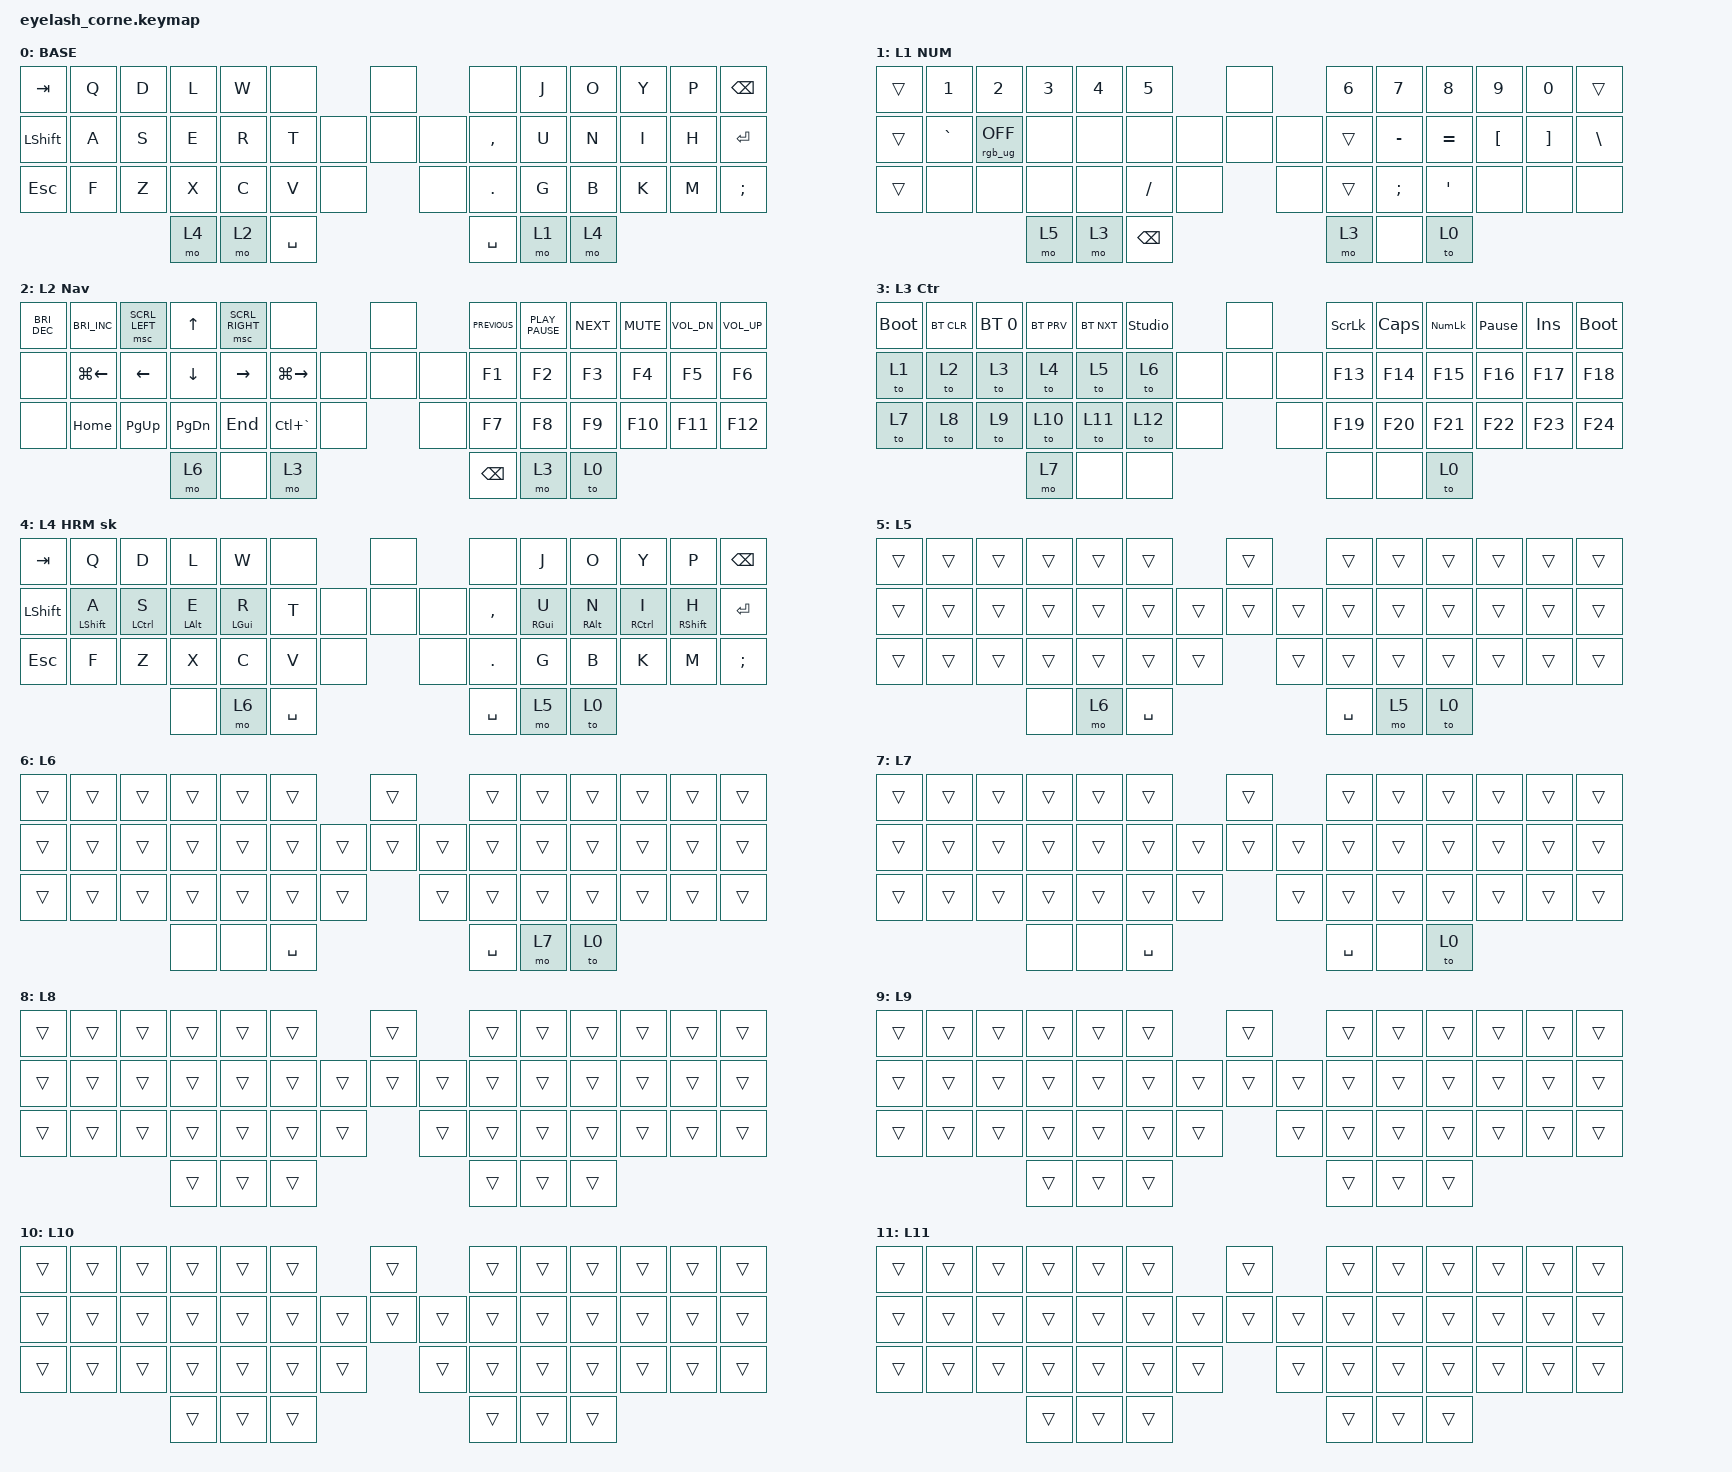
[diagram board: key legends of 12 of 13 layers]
#define ZMK_POINTING_DEFAULT_MOVE_VAL 1200  // 600
#define ZMK_POINTING_DEFAULT_SCRL_VAL 25   // 10

#include <input/processors.dtsi>
#include <zephyr/dt-bindings/input/input-event-codes.h>
#include <behaviors.dtsi>
#include <dt-bindings/zmk/bt.h>
#include <dt-bindings/zmk/keys.h>
#include <dt-bindings/zmk/pointing.h>
#include <dt-bindings/zmk/rgb.h>

&mmv_input_listener { input-processors = <&zip_xy_scaler 2 1>; };

&msc_input_listener { input-processors = <&zip_scroll_scaler 2 1>; };

/ {
    behaviors {
        td0: td0 {
            compatible = "zmk,behavior-tap-dance";
            display-name = "Shift/Caps Lock Tap Dance";
            #binding-cells = <0>;
            bindings = <&kp LEFT_SHIFT>, <&kp CAPS>;
        };
    };

    scroll_encoder: scroll_encoder {
        compatible = "zmk,behavior-sensor-rotate";
        #sensor-binding-cells = <0>;
        bindings = <&msc SCRL_DOWN>, <&msc SCRL_UP>;

        tap-ms = <100>;
    };

    keymap {
        compatible = "zmk,keymap";

        base {
            display-name = "BASE";
            bindings = <
&kp TAB    &kp Q  &kp D  &kp L  &kp W  &none                      &none         &none      &kp J  &kp O  &kp Y  &kp P  &kp BSPC
&kp LSHFT  &kp A  &kp S  &kp E  &kp R  &kp T               &none  &none  &none  &kp COMMA  &kp U  &kp N  &kp I  &kp H  &kp RET
&kp ESC    &kp F  &kp Z  &kp X  &kp C  &kp V      &none           &none         &kp DOT    &kp G  &kp B  &kp K  &kp M  &kp SEMI
                         &mo 4  &mo 2  &kp SPACE                                &kp SPACE  &mo 1  &mo 4
            >;
        };

        L1_Num {
            display-name = "L1 NUM";
            bindings = <
&trans  &kp N1     &kp N2           &kp N3  &kp N4  &kp N5                         &none         &kp N6  &kp N7     &kp N8     &kp N9    &kp N0    &trans
&trans  &kp GRAVE  &rgb_ug RGB_OFF  &none   &none   &none                   &none  &none  &none  &trans  &kp MINUS  &kp EQUAL  &kp LBKT  &kp RBKT  &kp BSLH
&trans  &none      &none            &none   &none   &kp FSLH       &none           &none         &trans  &kp SEMI   &kp SQT    &none     &none     &none
                                    &mo 5   &mo 3   &kp BACKSPACE                                &mo 3   &none      &to 0
            >;
        };

        L2_Nav {
            display-name = "L2 Nav";
            bindings = <
&kp C_BRIGHTNESS_DEC  &kp C_BRIGHTNESS_INC  &msc SCRL_LEFT  &kp UP         &msc SCRL_RIGHT  &none                          &none         &kp K_PREVIOUS  &kp K_PLAY_PAUSE  &kp K_NEXT  &kp K_MUTE  &kp K_VOL_DN  &kp K_VOLUME_UP
&none                 &kp LG(LEFT)          &kp LEFT        &kp DOWN       &kp RIGHT        &kp LG(RIGHT)           &none  &none  &none  &kp F1          &kp F2            &kp F3      &kp F4      &kp F5        &kp F6
&none                 &kp HOME              &kp PAGE_UP     &kp PAGE_DOWN  &kp END          &kp LC(GRAVE)  &none           &none         &kp F7          &kp F8            &kp F9      &kp F10     &kp F11       &kp F12
                                                            &mo 6          &none            &mo 3                                        &kp BACKSPACE   &mo 3             &to 0
            >;
        };

        L3_FN2_Ctr {
            display-name = "L3 Ctr";
            bindings = <
&bootloader  &bt BT_CLR  &bt BT_SEL 0  &bt BT_PRV  &bt BT_NXT  &studio_unlock                  &none         &kp SCROLLLOCK  &kp CAPS  &kp KP_NUMLOCK  &kp PAUSE_BREAK  &kp INSERT  &bootloader
&to 1        &to 2       &to 3         &to 4       &to 5       &to 6                    &none  &none  &none  &kp F13         &kp F14   &kp F15         &kp F16          &kp F17     &kp F18
&to 7        &to 8       &to 9         &to 10      &to 11      &to 12          &none           &none         &kp F19         &kp F20   &kp F21         &kp F22          &kp F23     &kp F24
                                       &mo 7       &none       &none                                         &none           &none     &to 0
            >;
        };

        L4_HRM {
            display-name = "L4 HRM sk";
            bindings = <
&kp TAB    &kp Q         &kp D        &kp L       &kp W       &none                      &none         &none      &kp J       &kp O       &kp Y        &kp P         &kp BSPC
&kp LSHFT  &mt LSHIFT A  &mt LCTRL S  &mt LALT E  &mt LGUI R  &kp T               &none  &none  &none  &kp COMMA  &mt RGUI U  &mt RALT N  &mt RCTRL I  &mt RSHIFT H  &kp RET
&kp ESC    &kp F         &kp Z        &kp X       &kp C       &kp V      &none           &none         &kp DOT    &kp G       &kp B       &kp K        &kp M         &kp SEMI
                                      &none       &mo 6       &kp SPACE                                &kp SPACE  &mo 5       &to 0
            >;
        };

        layer_5 {
            display-name = "L5";
            bindings = <
&trans  &trans  &trans  &trans  &trans  &trans                       &trans          &trans     &trans  &trans  &trans  &trans  &trans
&trans  &trans  &trans  &trans  &trans  &trans               &trans  &trans  &trans  &trans     &trans  &trans  &trans  &trans  &trans
&trans  &trans  &trans  &trans  &trans  &trans     &trans            &trans          &trans     &trans  &trans  &trans  &trans  &trans
                        &none   &mo 6   &kp SPACE                                    &kp SPACE  &mo 5   &to 0
            >;
        };

        layer_6 {
            display-name = "L6";
            bindings = <
&trans  &trans  &trans  &trans  &trans  &trans                       &trans          &trans     &trans  &trans  &trans  &trans  &trans
&trans  &trans  &trans  &trans  &trans  &trans               &trans  &trans  &trans  &trans     &trans  &trans  &trans  &trans  &trans
&trans  &trans  &trans  &trans  &trans  &trans     &trans            &trans          &trans     &trans  &trans  &trans  &trans  &trans
                        &none   &none   &kp SPACE                                    &kp SPACE  &mo 7   &to 0
            >;
        };

        layer_7 {
            display-name = "L7";
            bindings = <
&trans  &trans  &trans  &trans  &trans  &trans                       &trans          &trans     &trans  &trans  &trans  &trans  &trans
&trans  &trans  &trans  &trans  &trans  &trans               &trans  &trans  &trans  &trans     &trans  &trans  &trans  &trans  &trans
&trans  &trans  &trans  &trans  &trans  &trans     &trans            &trans          &trans     &trans  &trans  &trans  &trans  &trans
                        &none   &none   &kp SPACE                                    &kp SPACE  &none   &to 0
            >;
        };

        layer_8 {
            display-name = "L8";
            bindings = <
&trans  &trans  &trans  &trans  &trans  &trans                    &trans          &trans  &trans  &trans  &trans  &trans  &trans
&trans  &trans  &trans  &trans  &trans  &trans            &trans  &trans  &trans  &trans  &trans  &trans  &trans  &trans  &trans
&trans  &trans  &trans  &trans  &trans  &trans  &trans            &trans          &trans  &trans  &trans  &trans  &trans  &trans
                        &trans  &trans  &trans                                    &trans  &trans  &trans
            >;
        };

        layer_9 {
            display-name = "L9";
            bindings = <
&trans  &trans  &trans  &trans  &trans  &trans                    &trans          &trans  &trans  &trans  &trans  &trans  &trans
&trans  &trans  &trans  &trans  &trans  &trans            &trans  &trans  &trans  &trans  &trans  &trans  &trans  &trans  &trans
&trans  &trans  &trans  &trans  &trans  &trans  &trans            &trans          &trans  &trans  &trans  &trans  &trans  &trans
                        &trans  &trans  &trans                                    &trans  &trans  &trans
            >;
        };

        layer_10 {
            display-name = "L10";
            bindings = <
&trans  &trans  &trans  &trans  &trans  &trans                    &trans          &trans  &trans  &trans  &trans  &trans  &trans
&trans  &trans  &trans  &trans  &trans  &trans            &trans  &trans  &trans  &trans  &trans  &trans  &trans  &trans  &trans
&trans  &trans  &trans  &trans  &trans  &trans  &trans            &trans          &trans  &trans  &trans  &trans  &trans  &trans
                        &trans  &trans  &trans                                    &trans  &trans  &trans
            >;
        };

        layer_11 {
            display-name = "L11";
            bindings = <
&trans  &trans  &trans  &trans  &trans  &trans                    &trans          &trans  &trans  &trans  &trans  &trans  &trans
&trans  &trans  &trans  &trans  &trans  &trans            &trans  &trans  &trans  &trans  &trans  &trans  &trans  &trans  &trans
&trans  &trans  &trans  &trans  &trans  &trans  &trans            &trans          &trans  &trans  &trans  &trans  &trans  &trans
                        &trans  &trans  &trans                                    &trans  &trans  &trans
            >;
        };

        layer_12 {
            display-name = "L12";
            bindings = <
&trans  &trans  &trans  &trans  &trans  &trans                    &trans          &trans  &trans  &trans  &trans  &trans  &trans
&trans  &trans  &trans  &trans  &trans  &trans            &trans  &trans  &trans  &trans  &trans  &trans  &trans  &trans  &trans
&trans  &trans  &trans  &trans  &trans  &trans  &trans            &trans          &trans  &trans  &trans  &trans  &trans  &trans
                        &trans  &trans  &trans                                    &trans  &trans  &trans
            >;
        };
    };
};
